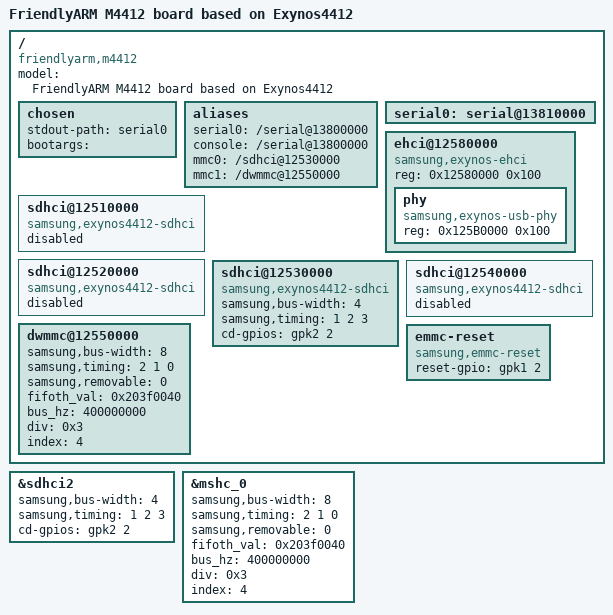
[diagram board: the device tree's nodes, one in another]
// SPDX-License-Identifier: GPL-2.0+
/*
 * Odroid-U3/X2 board device tree source
 *
 * Copyright (c) 2014 Samsung Electronics Co., Ltd.
 *             http://www.samsung.com
 */

/dts-v1/;
#include "exynos4412.dtsi"

/ {
       model = "FriendlyARM M4412 board based on Exynos4412";
       compatible = "friendlyarm,m4412", "samsung,exynos4412", "samsung,exynos4";

       chosen {
               stdout-path = "serial0";
               bootargs ="";
       };
       aliases {
               serial0 = "/serial@13800000";
               console = "/serial@13800000";
               //mmc0 = &mshc_0;
               //mmc1 = &sdhci2;
               mmc0 = "/sdhci@12530000";
               mmc1 = "/dwmmc@12550000";
       };

       serial0:serial@13810000 {
               status = "okay";
       };

       ehci@12580000 {
               compatible = "samsung,exynos-ehci";
               reg = <0x12580000 0x100>;
               #address-cells = <1>;
               #size-cells = <1>;
               phy {
                       compatible = "samsung,exynos-usb-phy";
                       reg = <0x125B0000 0x100>;
               };
       };
       sdhci@12510000 {
                compatible = "samsung,exynos4412-sdhci";
                        status = "disabled";
       };

       sdhci@12520000 {
                compatible = "samsung,exynos4412-sdhci";
                status = "disabled";
       };

        sdhci@12530000 {
                 compatible = "samsung,exynos4412-sdhci";
                 samsung,bus-width = <4>;
                  samsung,timing = <1 2 3>;
                  cd-gpios = <&gpk2 2 0>;
        };

        sdhci@12540000 {
                compatible = "samsung,exynos4412-sdhci";
                status = "disabled";
        };
       dwmmc@12550000 {
               samsung,bus-width = <8>;
               samsung,timing = <2 1 0>;
               samsung,removable = <0>;
               fifoth_val = <0x203f0040>;
               bus_hz = <400000000>;
               div = <0x3>;
               index = <4>;
       };
       emmc-reset {
               compatible = "samsung,emmc-reset";
               reset-gpio = <&gpk1 2 0>;
       };
};

&sdhci2 {
       samsung,bus-width = <4>;
       samsung,timing = <1 2 3>;
       cd-gpios = <&gpk2 2 0>;
       status = "okay";
};

&mshc_0 {
       samsung,bus-width = <8>;
       samsung,timing = <2 1 0>;
       samsung,removable = <0>;
       fifoth_val = <0x203f0040>;
       bus_hz = <400000000>;
       div = <0x3>;
       index = <4>;
       status = "okay";
};
